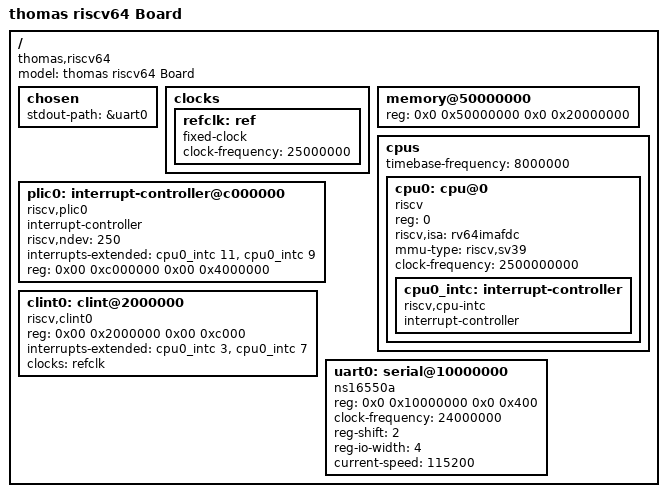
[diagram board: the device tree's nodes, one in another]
/*
 * Copyright (c) 2024 Thomas
 */

/dts-v1/;

/ {
       model = "thomas riscv64 Board";
       compatible = "thomas,riscv64";
       #address-cells = <2>;
       #size-cells = <2>;

       chosen {
               stdout-path = &uart0;
       };

       clocks {
               bootph-all;
               refclk: ref {
                       bootph-all;
                       compatible = "fixed-clock";
                       #clock-cells = <0>;
                       clock-frequency = <25000000>;
               };
       };

        memory@50000000 {
                bootph-all;
                device_type = "memory";
                reg = <0x0 0x50000000 0x0 0x20000000>;
        };

        cpus {
                bootph-all;
                #address-cells = <1>;
                #size-cells = <0>;
                timebase-frequency = <8000000>;
                cpu0: cpu@0 {
                        bootph-all;
                        device_type = "cpu";
                        reg = <0>;
                        status = "okay";
                        compatible = "riscv";
                        riscv,isa = "rv64imafdc";
                        mmu-type = "riscv,sv39";
                        clock-frequency = <2500000000>;
                        cpu0_intc: interrupt-controller {
                                bootph-all;
                                #interrupt-cells = <1>;
                                interrupt-controller;
                                compatible = "riscv,cpu-intc";
                        };
                };

        };

        plic0: interrupt-controller@c000000 {
                bootph-all;
                #interrupt-cells = <1>;
                compatible = "riscv,plic0";
                interrupt-controller;
                riscv,ndev = <250>;
		interrupts-extended = <&cpu0_intc 11>, <&cpu0_intc 9>;
                reg = <0x00 0xc000000 0x00 0x4000000>;
        };

        clint0: clint@2000000 {
                bootph-all;
                compatible = "riscv,clint0";
                reg = <0x00 0x2000000 0x00 0xc000>;
		interrupts-extended = <&cpu0_intc 3 &cpu0_intc 7>;
                clocks = <&refclk>;
        };
/*
        sdio_0: sdio-host@400240000 {
                bootph-all;
                compatible = "thomas,thomas-sdhci";
                reg = <0x4 0x240000 0x0 0x10000>;
                clocks = <&refclk>;
                max-frequency = <5000000>;
                no-1-8-v;
                no-sdio;
                status = "okay";
                non-removable;
        };
*/
       uart0: serial@10000000 {
               bootph-all;
               compatible = "ns16550a";
               reg = <0x0 0x10000000 0x0 0x400>;
               clock-frequency = <24000000>;
               reg-shift = <2>;
               reg-io-width = <4>;
               current-speed = <115200>;
       };
};
